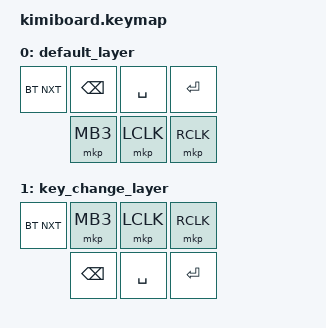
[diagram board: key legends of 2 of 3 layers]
#include <behaviors.dtsi>
#include <dt-bindings/zmk/bt.h>
#include <dt-bindings/zmk/keys.h>
#include <dt-bindings/zmk/mouse.h>
#include <dt-bindings/zmk/pointing.h>
#include <behaviors/rgbled_widget.dtsi>
#include <input/processors.dtsi>

&trackball {
    scroll-layers = <2>;
//  automouse-layer = <3>;

};


/ {
    keymap {
        compatible = "zmk,keymap";

        default_layer {
            bindings = <
                // row0左から右へ（一番左のキーはリセットボタン）
                &bt BT_NXT  &kp BACKSPACE  &kp SPACE  &kp ENTER
                            &mkp MB3       &mkp LCLK  &mkp RCLK
            >;
	};

    key_change_layer {
            bindings = <
                &bt BT_NXT  &mkp MB3       &mkp LCLK  &mkp RCLK
                            &kp BACKSPACE  &kp SPACE  &kp ENTER
        >;
    };

    scroll_layer {
            bindings = <
                &trans  &trans  &trans  &trans
                &trans  &trans  &trans  &trans
        >;
    };
    
    //  auto_mouse_layer {
    //      bindings = <
    //          &trans  &mkp MB3  &mkp LCLK  &mkp RCLK
    //  >;
    //  };

    };

    combos {
        compatible = "zmk,combos";

        // Key4 + 5 = (□ - □ □ □)
        //            (    ■ ■ □)
			// スクロールレイヤー

        combo_layer1 {
            bindings = <&mo 2>;
            key-positions = <4 5>;
            timeout-ms = <50>;
        };
        
        // Key1 + 4 = (□ - ■ □ □)
        //            (    ■ □ □)
			// タップでLANGUAGE_2へ切り替え

        combo_layer2 {
            bindings = <&kp LANGUAGE_2>;
            key-positions = <1 4>;
            timeout-ms = <50>;
        };

        // Key3 + 6 = (□ - □ □ ■)
        //            (    □ □ ■)
			// タップでLANGUAGE_1へ切り替え

        combo_layer3 {
            bindings = <&kp LANGUAGE_1>;
            key-positions = <3 6>;
            timeout-ms = <50>;
        };

        // Key1 + 3 = (□ -  ■ □ ■)
        //            (□ -  □ □ □)
			// 1番レイヤーをトグル(上段と下段のキーを入れ替え)

        combo_layer4 {
            bindings = <&tog 1>;
            key-positions = <1 3>;
            timeout-ms = <50>;
        };

		// Key1 + 2 + 4 + 5 = (□ - ■ ■ □)
        //                    (    ■ ■ □)
			// 接続先を変更（1→3トグル）

        combo_layer5 {
            bindings = <&bt BT_NXT>;
            key-positions = <1 2 4 5>;
            timeout-ms = <50>;
        };

		// Key2 + 3 + 5 + 6 = (□ - □ ■ ■)
        //                    (    □ ■ ■)
			// 現在の接続先のBT接続情報を消去

        combo_layer6 {
            bindings = <&bt BT_CLR>;
            key-positions = <2 3 5 6>;
            timeout-ms = <50>;
        };


    };

};
